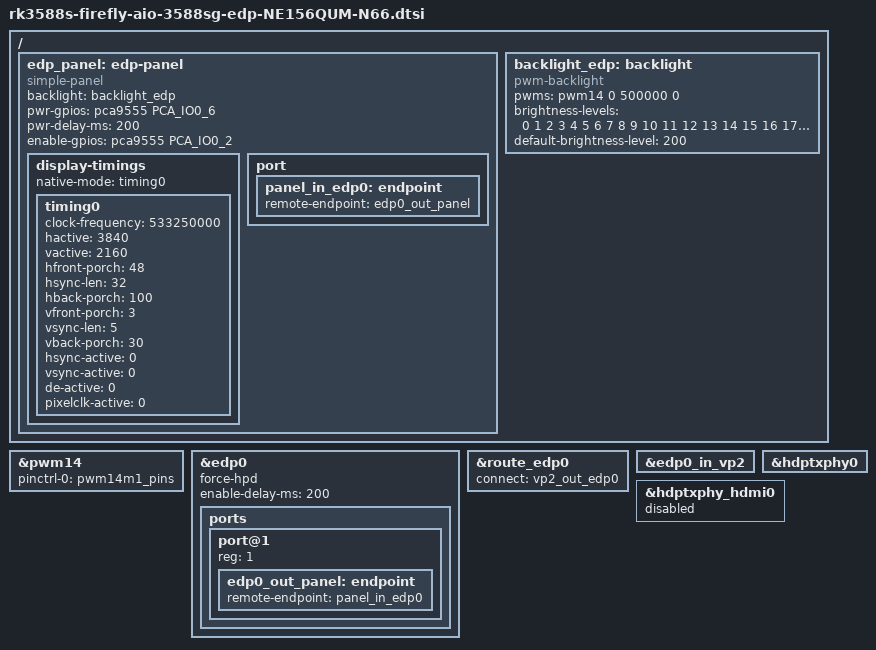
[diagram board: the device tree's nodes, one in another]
// SPDX-License-Identifier: (GPL-2.0+ OR MIT)
/*
 * Copyright (c) 2020 Rockchip Electronics Co., Ltd.
 *
 */

/ {
    edp_panel: edp-panel {
        compatible = "simple-panel";
        status = "okay";
        //bus-format = <MEDIA_BUS_FMT_RBG888_1X24>;
        backlight = <&backlight_edp>;
        pwr-gpios = <&pca9555 PCA_IO0_6 GPIO_ACTIVE_HIGH>;//vcc
        pwr-delay-ms = <200>;
        enable-gpios = <&pca9555 PCA_IO0_2 GPIO_ACTIVE_HIGH>; // EDP_BL_EN
        display-timings {
            native-mode = <&timing0>;
            timing0: timing0 {
                clock-frequency = <533250000>;  // Min 355.52 / Typ 533.25 / Max 586.6  (MHz)
                hactive = <3840>;
                vactive = <2160>;
                hfront-porch = <48>; 
                hsync-len = <32>;
                hback-porch = <100>;
                vfront-porch = <3>;
                vsync-len = <5>;
                vback-porch = <30>;
                hsync-active = <0>;
                vsync-active = <0>;
                de-active = <0>;
                pixelclk-active = <0>;
            };
        };

        port {
            panel_in_edp0: endpoint {
                remote-endpoint = <&edp0_out_panel>;
            };
        };
    };

    backlight_edp: backlight {
        status = "okay";
        compatible = "pwm-backlight";
        //enable-gpios = <&pca9555 PCA_IO0_2 GPIO_ACTIVE_HIGH>; // EDP_BL_EN
        pwms = <&pwm14 0 500000 0>;
        brightness-levels = <
              0   1   2   3   4   5   6   7
              8   9  10  11  12  13  14  15
             16  17  18  19  20  21  22  23
             24  25  26  27  28  29  30  31
             32  33  34  35  36  37  38  39
             40  41  42  43  44  45  46  47
             48  49  50  51  52  53  54  55
             56  57  58  59  60  61  62  63
             64  65  66  67  68  69  70  71
             72  73  74  75  76  77  78  79
             80  81  82  83  84  85  86  87
             88  89  90  91  92  93  94  95
             96  97  98  99 100 101 102 103
            104 105 106 107 108 109 110 111
            112 113 114 115 116 117 118 119
            120 121 122 123 124 125 126 127
            128 129 130 131 132 133 134 135
            136 137 138 139 140 141 142 143
            144 145 146 147 148 149 150 151
            152 153 154 155 156 157 158 159
            160 161 162 163 164 165 166 167
            168 169 170 171 172 173 174 175
            176 177 178 179 180 181 182 183
            184 185 186 187 188 189 190 191
            192 193 194 195 196 197 198 199
            200 201 202 203 204 205 206 207
            208 209 210 211 212 213 214 215
            216 217 218 219 220 221 222 223
            224 225 226 227 228 229 230 231
            232 233 234 235 236 237 238 239
            240 241 242 243 244 245 246 247
            248 249 250 251 252 253 254 255>;
        default-brightness-level = <200>;
    };
};

&pwm14 {
    pinctrl-0 = <&pwm14m1_pins>;
    status = "okay";
};


&edp0 {
    // panel-self-test;
    // analogix,video-bist-enable;
	force-hpd;
	// hpd-gpios = <&gpio1 RK_PA6 GPIO_ACTIVE_HIGH>;
	status = "okay";
	enable-delay-ms = <200>;

	ports {
        port@1 {
            reg = <1>;
            edp0_out_panel: endpoint {
                remote-endpoint = <&panel_in_edp0>;
            };
        };
    };
};

&route_edp0 {
	status = "okay";
	connect = <&vp2_out_edp0>;
};

&edp0_in_vp2 {
	status = "okay";
};

&hdptxphy0 {
	status = "okay";
};

&hdptxphy_hdmi0 {
	status = "disabled";
};
